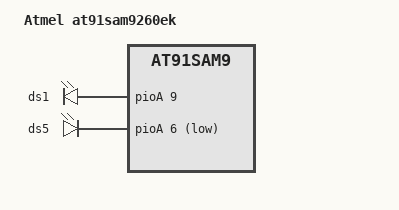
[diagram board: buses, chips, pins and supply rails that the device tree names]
/*
 * SAM9260EK eval board - Warner Losh public domain
 *
 * $FreeBSD$
 */
/dts-v1/;
#include "sam9260ek_common.dtsi"

/ {
	model = "Atmel at91sam9260ek";
	compatible = "atmel,at91sam9260ek", "atmel,at91sam9260", "atmel,at91sam9";

	leds {
		compatible = "gpio-leds";

		ds1 {
			label = "ds1";
			gpios = <&pioA 9 0>;
			linux,default-trigger = "heartbeat";
		};

		ds5 {
			label = "ds5";
			gpios = <&pioA 6 1>;
		};
	};

	aliases {
		dbgu = &dbgu;
	};


	chosen {
		stdin = "dbgu";
		stdout = "dbgu";
	};
};
